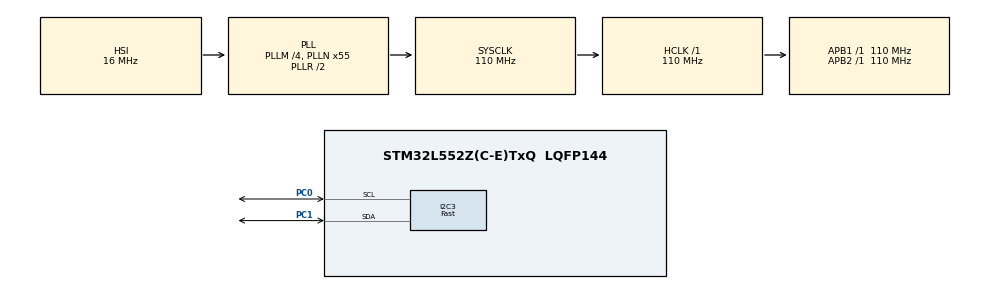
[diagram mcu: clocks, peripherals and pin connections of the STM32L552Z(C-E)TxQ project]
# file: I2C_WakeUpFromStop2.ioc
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I2C3.AddressingMode=I2C_ADDRESSINGMODE_7BIT
I2C3.Analog_Filter=I2C_ANALOGFILTER_ENABLE
I2C3.DualAddressMode=I2C_DUALADDRESS_DISABLE
I2C3.GeneralCallMode=I2C_GENERALCALL_DISABLE
I2C3.I2C_Coeff_DF=0
I2C3.I2C_Fall_Time=10
I2C3.I2C_Rise_Time=50
I2C3.I2C_Speed_Mode=I2C_Fast
I2C3.NoStretchMode=I2C_NOSTRETCH_DISABLE
I2C3.OwnAddress=I2C_ADDRESS/2
I2C3.Speed=100
I2C3.Timing=0x0020098E
Mcu.Family=STM32L5
Mcu.Name=STM32L552Z(C-E)TxQ
Mcu.Package=LQFP144
Mcu.UserConstants=I2C_ADDRESS,0xCA
NVIC.I2C3_EV_IRQn=true\:0\:0\:false\:false\:true\:true\:true\:true
NVIC.PriorityGroup=NVIC_PRIORITYGROUP_3
PC0.GPIO_Pu=GPIO_PULLUP
PC0.Mode=I2C
PC0.Signal=I2C3_SCL
PC1.GPIO_Pu=GPIO_PULLUP
PC1.Mode=I2C
PC1.Signal=I2C3_SDA
ProjectManager.HeapSize=0x200
ProjectManager.StackSize=0x400
ProjectManager.TargetToolchain=EWARM V8.32
RCC.ADCFreq_Value=48000000
RCC.AHBFreq_Value=110000000
RCC.APB1Freq_Value=110000000
RCC.APB1TimFreq_Value=110000000
RCC.APB2Freq_Value=110000000
RCC.APB2TimFreq_Value=110000000
RCC.CK48CLockSelection=RCC_USBCLKSOURCE_MSI
RCC.CortexFreq_Value=110000000
RCC.DATA_CACHE_ENABLE=0
RCC.HCLKFreq_Value=110000000
RCC.HSE_VALUE=16000000
RCC.HSI48_VALUE=48000000
RCC.HSI_VALUE=16000000
RCC.I2C3CLockSelection=RCC_I2C3CLKSOURCE_HSI
RCC.INSTRUCTION_CACHE_ENABLE=0
RCC.LPTIM1CLockSelectionVirtual=RCC_LPTIM1CLKSOURCE_LSE
RCC.LPUART1CLockSelectionVirtual=RCC_LPUART1CLKSOURCE_HSI
RCC.LSE_VALUE=32768
RCC.MSI_VALUE=4000000
RCC.PLLM=4
RCC.PLLN=55
RCC.PLLSAI1N=24
RCC.PLLSourceVirtual=RCC_PLLSOURCE_HSI
RCC.RTCClockSelection=RCC_RTCCLKSOURCE_LSE
RCC.SYSCLKFreq_VALUE=110000000
RCC.SYSCLKSource=RCC_SYSCLKSOURCE_PLLCLK
RCC.USBFreq_Value=4000000
RCC.VCOOutputFreq_Value=220000000
VP_ICACHE_VS_ICACHE.Mode=DirectMappedCache
VP_PWR_VS_DBSignals.Mode=DisableDeadBatterySignals
board=custom

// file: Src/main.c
/* USER CODE BEGIN Header */
/**
  ******************************************************************************
  * @file    I2C/I2C_WakeUpFromStop2/Src/main.c
  * @author  MCD Application Team
  * @brief   This sample code shows how to use STM32L5xx I2C HAL API to transmit
  *          and receive a data buffer with a communication process in stop mode 2
  *          based on IT transfer.
  *          The communication is done using 2 Boards.
  ******************************************************************************
  * @attention
  *
  * Copyright (c) 2019 STMicroelectronics.
  * All rights reserved.
  *
  * This software is licensed under terms that can be found in the LICENSE file
  * in the root directory of this software component.
  * If no LICENSE file comes with this software, it is provided AS-IS.
  *
  ******************************************************************************
  */
/* USER CODE END Header */
#include "main.h"

/* USER CODE BEGIN PD */
/* Uncomment this line to use the board as master, if not it is used as slave */
#define MASTER_BOARD
/* USER CODE END PD */

I2C_HandleTypeDef hi2c3;

/* USER CODE BEGIN PV */
/* Buffer used for transmission */
uint8_t aTxBuffer[] = " ****I2C_TwoBoards communication wake up from stop mode 2 based on IT****  ****I2C_TwoBoards communication wake up from stop mode 2 based on IT****  ****I2C_TwoBoards communication wake up from stop mode 2 based on IT**** ";

/* Buffer used for reception */
uint8_t aRxBuffer[RXBUFFERSIZE];
/* USER CODE END PV */

void SystemClock_Config(void);
static void MX_GPIO_Init(void);
static void MX_ICACHE_Init(void);
static void MX_I2C3_Init(void);
/* USER CODE BEGIN PFP */
/* Private function prototypes -----------------------------------------------*/
static uint16_t Buffercmp(uint8_t* pBuffer1, uint8_t* pBuffer2, uint16_t BufferLength);

/* USER CODE END PFP */

int main(void)
{

  /* MCU Configuration--------------------------------------------------------*/

  /* Reset of all peripherals, Initializes the Flash interface and the Systick. */
  HAL_Init();

  /* Configure the system clock */
  SystemClock_Config();

  /* Initialize all configured peripherals */
  MX_GPIO_Init();
  MX_ICACHE_Init();
  MX_I2C3_Init();
  /* USER CODE BEGIN 2 */
  /* Configure LED2, LED1 and LED3 */
  BSP_LED_Init(LED2);
  BSP_LED_Init(LED3);
  BSP_LED_Init(LED1);

#ifdef MASTER_BOARD

  /* Configure User push-button */
  BSP_PB_Init(BUTTON_USER, BUTTON_MODE_GPIO);

  /* Wait for User push-button press before starting the Communication */
  while (BSP_PB_GetState(BUTTON_USER) != GPIO_PIN_SET)
  {
  }

  /* Wait for User push-button release before starting the Communication */
  while (BSP_PB_GetState(BUTTON_USER) != GPIO_PIN_RESET)
  {
  }

  /* The board sends the message and expects to receive it back */

  /*##- Start the transmission process #####################################*/
  /* While the I2C in reception process, user can transmit data through
     "aTxBuffer" buffer */
  do
  {
    if(HAL_I2C_Master_Transmit_IT(&hi2c3, (uint16_t)I2C_ADDRESS, (uint8_t*)aTxBuffer, TXBUFFERSIZE)!= HAL_OK)
    {
      /* Error_Handler() function is called when error occurs. */
      Error_Handler();
    }

    /*##- Wait for the end of the transfer #################################*/
    /*  Before starting a new communication transfer, you need to check the current
        state of the peripheral; if it's busy you need to wait for the end of current
        transfer before starting a new one.
        For simplicity reasons, this example is just waiting till the end of the
        transfer, but application may perform other tasks while transfer operation
        is ongoing. */
    while (HAL_I2C_GetState(&hi2c3) != HAL_I2C_STATE_READY)
    {
    }

    /* When Acknowledge failure occurs (Slave don't acknowledge it's address)
       Master restarts communication */
  }
  while(HAL_I2C_GetError(&hi2c3) == HAL_I2C_ERROR_AF);

  /* Wait for User push-button press before starting the Communication */
  while (BSP_PB_GetState(BUTTON_USER) != GPIO_PIN_SET)
  {
  }

  /* Wait for User push-button release before starting the Communication */
  while (BSP_PB_GetState(BUTTON_USER) != GPIO_PIN_RESET)
  {
  }

  /*##- Put I2C peripheral in reception process ###########################*/
  do
  {
    if(HAL_I2C_Master_Receive_IT(&hi2c3, (uint16_t)I2C_ADDRESS, (uint8_t *)aRxBuffer, RXBUFFERSIZE) != HAL_OK)
    {
      /* Error_Handler() function is called when error occurs. */
      Error_Handler();
    }

    /*##- Wait for the end of the transfer #################################*/
    /*  Before starting a new communication transfer, you need to check the current
        state of the peripheral; if it's busy you need to wait for the end of current
        transfer before starting a new one.
        For simplicity reasons, this example is just waiting till the end of the
        transfer, but application may perform other tasks while transfer operation
        is ongoing. */
    while (HAL_I2C_GetState(&hi2c3) != HAL_I2C_STATE_READY)
    {
    }

    /* When Acknowledge failure occurs (Slave don't acknowledge it's address)
       Master restarts communication */
  }
  while(HAL_I2C_GetError(&hi2c3) == HAL_I2C_ERROR_AF);

#else
  /*##- Enable I2C peripheral in wake up from stop mode 2 #################*/
  HAL_I2CEx_EnableWakeUp(&hi2c3);

  /*##- Put I2C peripheral in reception process ###########################*/
  if(HAL_I2C_Slave_Receive_IT(&hi2c3, (uint8_t *)aRxBuffer, RXBUFFERSIZE) != HAL_OK)
  {
    /* Transfer error in reception process */
    Error_Handler();
  }

  /* enter stop mode 2 */
  /* Turn LED1 on */
  BSP_LED_On(LED1);
  HAL_PWREx_EnterSTOP2Mode(PWR_STOPENTRY_WFI);

  /* ... STOP mode 2 ... */

  /* Wake Up from Stop mode 2 */
  /* Turn LED1 off */
  BSP_LED_Off(LED1);

  /*##- Wait for the end of the transfer ###################################*/
  /*  Before starting a new communication transfer, you need to check the current
      state of the peripheral; if it's busy you need to wait for the end of current
      transfer before starting a new one.
      For simplicity reasons, this example is just waiting till the end of the
      transfer, but application may perform other tasks while transfer operation
      is ongoing. */
  while (HAL_I2C_GetState(&hi2c3) != HAL_I2C_STATE_READY)
  {
  }

  /*##- Start the transmission process #####################################*/
  /* While the I2C in reception process, user can transmit data through
     "aTxBuffer" buffer */
  if(HAL_I2C_Slave_Transmit_IT(&hi2c3, (uint8_t*)aTxBuffer, TXBUFFERSIZE)!= HAL_OK)
  {
    /* Transfer error in transmission process */
    Error_Handler();
  }

  /* enter stop mode 2 */
  /* Turn LED1 on */
  BSP_LED_On(LED1);
  HAL_PWREx_EnterSTOP2Mode(PWR_STOPENTRY_WFI);

  /* ... STOP mode 2 ... */

  /* Wake Up from Stop mode 2 */
  /* Turn LED1 off */
  BSP_LED_Off(LED1);
#endif /* MASTER_BOARD */

  /*##- Wait for the end of the transfer ###################################*/
  /*  Before starting a new communication transfer, you need to check the current
      state of the peripheral; if it's busy you need to wait for the end of current
      transfer before starting a new one.
      For simplicity reasons, this example is just waiting till the end of the
      transfer, but application may perform other tasks while transfer operation
      is ongoing. */
  while (HAL_I2C_GetState(&hi2c3) != HAL_I2C_STATE_READY)
  {
  }

  /*##- Compare the sent and received buffers ##############################*/
  if(Buffercmp((uint8_t*)aTxBuffer,(uint8_t*)aRxBuffer,RXBUFFERSIZE))
  {
    /* Processing Error */
    Error_Handler();
  }
  /* USER CODE END 2 */

  /* Infinite loop */
  while (1)
  {

  }
}

void SystemClock_Config(void)
{
  RCC_OscInitTypeDef RCC_OscInitStruct = {0};
  RCC_ClkInitTypeDef RCC_ClkInitStruct = {0};

  /** Configure the main internal regulator output voltage
  */
  if (HAL_PWREx_ControlVoltageScaling(PWR_REGULATOR_VOLTAGE_SCALE0) != HAL_OK)
  {
    Error_Handler();
  }

  /** Initializes the RCC Oscillators according to the specified parameters
  * in the RCC_OscInitTypeDef structure.
  */
  RCC_OscInitStruct.OscillatorType = RCC_OSCILLATORTYPE_HSI;
  RCC_OscInitStruct.HSIState = RCC_HSI_ON;
  RCC_OscInitStruct.HSICalibrationValue = RCC_HSICALIBRATION_DEFAULT;
  RCC_OscInitStruct.PLL.PLLState = RCC_PLL_ON;
  RCC_OscInitStruct.PLL.PLLSource = RCC_PLLSOURCE_HSI;
  RCC_OscInitStruct.PLL.PLLM = 4;
  RCC_OscInitStruct.PLL.PLLN = 55;
  RCC_OscInitStruct.PLL.PLLP = RCC_PLLP_DIV7;
  RCC_OscInitStruct.PLL.PLLQ = RCC_PLLQ_DIV2;
  RCC_OscInitStruct.PLL.PLLR = RCC_PLLR_DIV2;
  if (HAL_RCC_OscConfig(&RCC_OscInitStruct) != HAL_OK)
  {
    Error_Handler();
  }

  /** Initializes the CPU, AHB and APB buses clocks
  */
  RCC_ClkInitStruct.ClockType = RCC_CLOCKTYPE_HCLK|RCC_CLOCKTYPE_SYSCLK
                              |RCC_CLOCKTYPE_PCLK1|RCC_CLOCKTYPE_PCLK2;
  RCC_ClkInitStruct.SYSCLKSource = RCC_SYSCLKSOURCE_PLLCLK;
  RCC_ClkInitStruct.AHBCLKDivider = RCC_SYSCLK_DIV1;
  RCC_ClkInitStruct.APB1CLKDivider = RCC_HCLK_DIV1;
  RCC_ClkInitStruct.APB2CLKDivider = RCC_HCLK_DIV1;

  if (HAL_RCC_ClockConfig(&RCC_ClkInitStruct, FLASH_LATENCY_5) != HAL_OK)
  {
    Error_Handler();
  }
}

static void MX_I2C3_Init(void)
{

  hi2c3.Instance = I2C3;
  hi2c3.Init.Timing = 0x0020098E;
  hi2c3.Init.OwnAddress1 = 202;
  hi2c3.Init.AddressingMode = I2C_ADDRESSINGMODE_7BIT;
  hi2c3.Init.DualAddressMode = I2C_DUALADDRESS_DISABLE;
  hi2c3.Init.OwnAddress2 = 0;
  hi2c3.Init.OwnAddress2Masks = I2C_OA2_NOMASK;
  hi2c3.Init.GeneralCallMode = I2C_GENERALCALL_DISABLE;
  hi2c3.Init.NoStretchMode = I2C_NOSTRETCH_DISABLE;
  if (HAL_I2C_Init(&hi2c3) != HAL_OK)
  {
    Error_Handler();
  }

  /** Configure Analogue filter
  */
  if (HAL_I2CEx_ConfigAnalogFilter(&hi2c3, I2C_ANALOGFILTER_ENABLE) != HAL_OK)
  {
    Error_Handler();
  }

  /** Configure Digital filter
  */
  if (HAL_I2CEx_ConfigDigitalFilter(&hi2c3, 0) != HAL_OK)
  {
    Error_Handler();
  }

}

static void MX_ICACHE_Init(void)
{

  /** Enable instruction cache in 1-way (direct mapped cache)
  */
  if (HAL_ICACHE_ConfigAssociativityMode(ICACHE_1WAY) != HAL_OK)
  {
    Error_Handler();
  }
  if (HAL_ICACHE_Enable() != HAL_OK)
  {
    Error_Handler();
  }

}

static void MX_GPIO_Init(void)
{

  /* GPIO Ports Clock Enable */
  __HAL_RCC_GPIOC_CLK_ENABLE();

}

/* USER CODE BEGIN 4 */
/**
  * @brief  Tx Transfer completed callback.
  * @param  I2cHandle: I2C handle.
  * @note   This example shows a simple way to report end of IT Tx transfer, and
  *         you can add your own implementation.
  * @retval None
  */
#ifdef MASTER_BOARD
void HAL_I2C_MasterTxCpltCallback(I2C_HandleTypeDef *I2cHandle)
{
  /* Toggle LED2: Transfer in transmission process is correct */
  BSP_LED_Toggle(LED2);
}
#else
void HAL_I2C_SlaveTxCpltCallback(I2C_HandleTypeDef *I2cHandle)
{
  /* Restore config: clock, GPIO... */
  SystemClock_Config();

  /* Restore GPIO configuration */
  BSP_LED_Init(LED2);
  BSP_LED_Init(LED1);

  /* Wake Up from Stop Mode 2 */
  /* Turn LED1 off */
  BSP_LED_Off(LED1);
  /* Turn off LED2: Transfer in transmission process is correct */
  BSP_LED_Off(LED2);
}
#endif /* MASTER_BOARD */

/**
  * @brief  Rx Transfer completed callback.
  * @param  I2cHandle: I2C handle
  * @note   This example shows a simple way to report end of IT Rx transfer, and
  *         you can add your own implementation.
  * @retval None
  */
#ifdef MASTER_BOARD
void HAL_I2C_MasterRxCpltCallback(I2C_HandleTypeDef *I2cHandle)
{
  /* Toggle LED2: Transfer in reception process is correct */
  BSP_LED_Toggle(LED2);
}
#else
void HAL_I2C_SlaveRxCpltCallback(I2C_HandleTypeDef *I2cHandle)
{
  /* Restore config: clock, GPIO... */
  SystemClock_Config();

  /* Restore GPIO configuration */
  BSP_LED_Init(LED2);
  BSP_LED_Init(LED1);

  /* Wake Up from Stop Mode 2 */
  /* Turn LED1 off */
  BSP_LED_Off(LED1);

  /* Turn On LED2: Transfer in reception process is correct */
  BSP_LED_On(LED2);
}
#endif /* MASTER_BOARD */

/**
  * @brief  I2C error callbacks.
  * @param  I2cHandle: I2C handle
  * @note   This example shows a simple way to report transfer error, and you can
  *         add your own implementation.
  * @retval None
  */
#ifdef MASTER_BOARD
void HAL_I2C_ErrorCallback(I2C_HandleTypeDef *I2cHandle)
{
  /* Turn LED3 on: Transfer error in reception/transmission process */
  BSP_LED_On(LED3);
}
#else
void HAL_I2C_ErrorCallback(I2C_HandleTypeDef *I2cHandle)
{
  /* Restore config: clock, GPIO... */
  SystemClock_Config();

  /** Error_Handler() function is called when error occurs.
    * 1- When Slave doesn't acknowledge its address, Master restarts communication.
    * 2- When Master doesn't acknowledge the last data transferred, Slave doesn't care in this example.
    */
  if (HAL_I2C_GetError(I2cHandle) != HAL_I2C_ERROR_AF)
  {
    /* Restore GPIO configuration */
    BSP_LED_Init(LED2);
    BSP_LED_Init(LED3);

    /* Turn Off LED2 */
    BSP_LED_Off(LED2);

    /* Turn On LED3 */
    BSP_LED_On(LED3);
  }
}
#endif /* MASTER_BOARD */

/**
  * @brief  Compares two buffers.
  * @param  pBuffer1, pBuffer2: buffers to be compared.
  * @param  BufferLength: buffer's length
  * @retval 0  : pBuffer1 identical to pBuffer2
  *         >0 : pBuffer1 differs from pBuffer2
  */
static uint16_t Buffercmp(uint8_t* pBuffer1, uint8_t* pBuffer2, uint16_t BufferLength)
{
  while (BufferLength--)
  {
    if ((*pBuffer1) != *pBuffer2)
    {
      return BufferLength;
    }
    pBuffer1++;
    pBuffer2++;
  }

  return 0;
}
/* USER CODE END 4 */

void Error_Handler(void)
{
  /* USER CODE BEGIN Error_Handler_Debug */
  /* User can add his own implementation to report the HAL error return state */
  /* Turn LED3 on */
  BSP_LED_On(LED3);
  while(1)
  {
  }
  /* USER CODE END Error_Handler_Debug */
}
#ifdef USE_FULL_ASSERT
/**
  * @brief  Reports the name of the source file and the source line number
  *         where the assert_param error has occurred.
  * @param  file: pointer to the source file name
  * @param  line: assert_param error line source number
  * @retval None
  */
void assert_failed(uint8_t *file, uint32_t line)
{
  /* USER CODE BEGIN 6 */
  /* User can add his own implementation to report the file name and line number,
    ex: printf("Wrong parameters value: file %s on line %d\r\n", file, line) */
  Error_Handler();
  /* USER CODE END 6 */
}
#endif /* USE_FULL_ASSERT */
